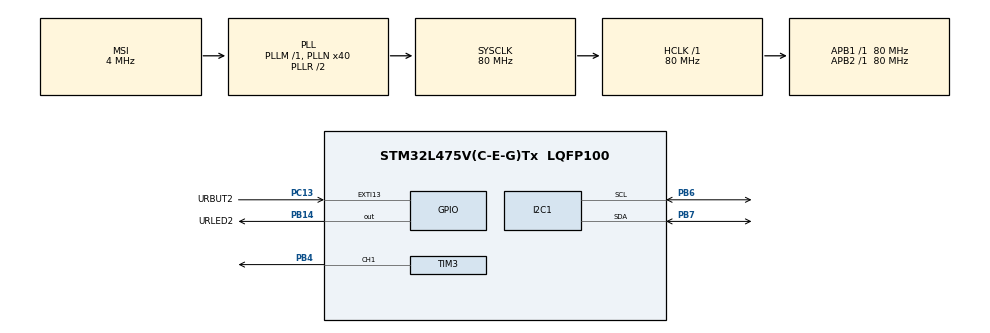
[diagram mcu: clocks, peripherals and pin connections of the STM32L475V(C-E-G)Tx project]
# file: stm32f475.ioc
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Mcu.Family=STM32L4
RCC.MSI_VALUE=4000000
PA14\ (JTCK-SWCLK).Mode=Serial_Wire
RCC.CortexFreq_Value=80000000
TIM3.AutoReloadPreload=TIM_AUTORELOAD_PRELOAD_DISABLE
PC13.Signal=GPXTI13
PB14.GPIO_Label=URLED2
PC13.GPIO_Label=URBUT2
RCC.SYSCLKSource=RCC_SYSCLKSOURCE_PLLCLK
ProjectManager.StackSize=0x400
PA14\ (JTCK-SWCLK).Signal=SYS_JTCK-SWCLK
ProjectManager.TargetToolchain=STM32CubeIDE
RCC.HCLKFreq_Value=80000000
RCC.APB2TimFreq_Value=80000000
TIM3.Period=999
PB6.Signal=I2C1_SCL
I2C1.Timing=0x10909CEC
PB6.Mode=I2C
RCC.LSE_VALUE=32768
RCC.AHBFreq_Value=80000000
TIM3.Channel-PWM\ Generation1\ CH1=TIM_CHANNEL_1
NVIC.EXTI15_10_IRQn=true\:9\:0\:true\:false\:true\:true\:true
PB14.Signal=GPIO_Output
RCC.HSE_VALUE=8000000
board=custom
RCC.VCOOutputFreq_Value=160000000
NVIC.TIM3_IRQn=true\:0\:0\:false\:false\:true\:true\:true
RCC.APB2Freq_Value=80000000
TIM3.Prescaler=1600
PB7.Signal=I2C1_SDA
SH.S_TIM3_CH1.0=TIM3_CH1,PWM Generation1 CH1
Mcu.Name=STM32L475V(C-E-G)Tx
PA13\ (JTMS-SWDIO).Mode=Serial_Wire
RCC.SYSCLKFreq_VALUE=80000000
Mcu.Package=LQFP100
PB7.Mode=I2C
ProjectManager.HeapSize=0x200
RCC.HSI_VALUE=16000000
NVIC.PriorityGroup=NVIC_PRIORITYGROUP_4
RCC.PLLN=40
RCC.APB1TimFreq_Value=80000000
PA13\ (JTMS-SWDIO).Signal=SYS_JTMS-SWDIO
RCC.APB1Freq_Value=80000000
VP_TIM3_VS_ClockSourceINT.Mode=Internal
PB4\ (NJTRST).Signal=S_TIM3_CH1

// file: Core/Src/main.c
/* USER CODE BEGIN Header */
/**
  ******************************************************************************
  * @file           : main.c
  * @brief          : Main program body
  ******************************************************************************
  * @attention
  *
  * <h2><center>&copy; Copyright (c) 2021 STMicroelectronics.
  * All rights reserved.</center></h2>
  *
  * This software component is licensed by ST under BSD 3-Clause license,
  * the "License"; You may not use this file except in compliance with the
  * License. You may obtain a copy of the License at:
  *                        opensource.org/licenses/BSD-3-Clause
  *
  ******************************************************************************
  */
/* USER CODE END Header */
#include "main.h"

I2C_HandleTypeDef hi2c1;

TIM_HandleTypeDef htim3;

void SystemClock_Config(void);
static void MX_GPIO_Init(void);
static void MX_TIM3_Init(void);
static void MX_I2C1_Init(void);

int main(void)
{

  /* MCU Configuration--------------------------------------------------------*/

  /* Reset of all peripherals, Initializes the Flash interface and the Systick. */
  HAL_Init();

  /* Configure the system clock */
  SystemClock_Config();

  /* Initialize all configured peripherals */
  MX_GPIO_Init();
  MX_TIM3_Init();
  MX_I2C1_Init();
  /* USER CODE BEGIN 2 */
  HAL_TIM_PWM_Start(&htim3, TIM_CHANNEL_1);
  uint32_t brightness=0;
  /* USER CODE END 2 */

  /* Infinite loop */
  /* USER CODE BEGIN WHILE */
  while (1)
  {
	  while( brightness < htim3.Init.Period)
	     {
	        brightness += 10;
         __HAL_TIM_SET_COMPARE(&htim3, TIM_CHANNEL_1, brightness);
	        HAL_Delay(1);

	     }
	  //PWM
//	  __HAL_TIM_SetCompare(&htim3,TIM_CHANNEL_1,100); //180
//	  HAL_Delay(1000);
//
//	  __HAL_TIM_SetCompare(&htim3,TIM_CHANNEL_1,75); //90
//	 HAL_Delay(1000);
//
//	 __HAL_TIM_SetCompare(&htim3,TIM_CHANNEL_1,50); //0
//	 HAL_Delay(1000);
	 // LED2(1000);
	 /* HAL_GPIO_TogglePin(URLED2_GPIO_Port, URLED2_Pin);
	  HAL_Delay(1000);
	  HAL_GPIO_WritePin(GPIOB, GPIO_PIN_14, GPIO_PIN_SET);
	  HAL_Delay(1000);
	  HAL_GPIO_WritePin(GPIOB, GPIO_PIN_14, GPIO_PIN_RESET);
	  HAL_Delay(1000);*/

    /* USER CODE END WHILE */

  }
}

void SystemClock_Config(void)
{
  RCC_OscInitTypeDef RCC_OscInitStruct = {0};
  RCC_ClkInitTypeDef RCC_ClkInitStruct = {0};
  RCC_PeriphCLKInitTypeDef PeriphClkInit = {0};

  /** Initializes the RCC Oscillators according to the specified parameters
  * in the RCC_OscInitTypeDef structure.
  */
  RCC_OscInitStruct.OscillatorType = RCC_OSCILLATORTYPE_MSI;
  RCC_OscInitStruct.MSIState = RCC_MSI_ON;
  RCC_OscInitStruct.MSICalibrationValue = 0;
  RCC_OscInitStruct.MSIClockRange = RCC_MSIRANGE_6;
  RCC_OscInitStruct.PLL.PLLState = RCC_PLL_ON;
  RCC_OscInitStruct.PLL.PLLSource = RCC_PLLSOURCE_MSI;
  RCC_OscInitStruct.PLL.PLLM = 1;
  RCC_OscInitStruct.PLL.PLLN = 40;
  RCC_OscInitStruct.PLL.PLLP = RCC_PLLP_DIV7;
  RCC_OscInitStruct.PLL.PLLQ = RCC_PLLQ_DIV2;
  RCC_OscInitStruct.PLL.PLLR = RCC_PLLR_DIV2;
  if (HAL_RCC_OscConfig(&RCC_OscInitStruct) != HAL_OK)
  {
    Error_Handler();
  }
  /** Initializes the CPU, AHB and APB buses clocks
  */
  RCC_ClkInitStruct.ClockType = RCC_CLOCKTYPE_HCLK|RCC_CLOCKTYPE_SYSCLK
                              |RCC_CLOCKTYPE_PCLK1|RCC_CLOCKTYPE_PCLK2;
  RCC_ClkInitStruct.SYSCLKSource = RCC_SYSCLKSOURCE_PLLCLK;
  RCC_ClkInitStruct.AHBCLKDivider = RCC_SYSCLK_DIV1;
  RCC_ClkInitStruct.APB1CLKDivider = RCC_HCLK_DIV1;
  RCC_ClkInitStruct.APB2CLKDivider = RCC_HCLK_DIV1;

  if (HAL_RCC_ClockConfig(&RCC_ClkInitStruct, FLASH_LATENCY_4) != HAL_OK)
  {
    Error_Handler();
  }
  PeriphClkInit.PeriphClockSelection = RCC_PERIPHCLK_I2C1;
  PeriphClkInit.I2c1ClockSelection = RCC_I2C1CLKSOURCE_PCLK1;
  if (HAL_RCCEx_PeriphCLKConfig(&PeriphClkInit) != HAL_OK)
  {
    Error_Handler();
  }
  /** Configure the main internal regulator output voltage
  */
  if (HAL_PWREx_ControlVoltageScaling(PWR_REGULATOR_VOLTAGE_SCALE1) != HAL_OK)
  {
    Error_Handler();
  }
}

static void MX_I2C1_Init(void)
{

  hi2c1.Instance = I2C1;
  hi2c1.Init.Timing = 0x10909CEC;
  hi2c1.Init.OwnAddress1 = 0;
  hi2c1.Init.AddressingMode = I2C_ADDRESSINGMODE_7BIT;
  hi2c1.Init.DualAddressMode = I2C_DUALADDRESS_DISABLE;
  hi2c1.Init.OwnAddress2 = 0;
  hi2c1.Init.OwnAddress2Masks = I2C_OA2_NOMASK;
  hi2c1.Init.GeneralCallMode = I2C_GENERALCALL_DISABLE;
  hi2c1.Init.NoStretchMode = I2C_NOSTRETCH_DISABLE;
  if (HAL_I2C_Init(&hi2c1) != HAL_OK)
  {
    Error_Handler();
  }
  /** Configure Analogue filter
  */
  if (HAL_I2CEx_ConfigAnalogFilter(&hi2c1, I2C_ANALOGFILTER_ENABLE) != HAL_OK)
  {
    Error_Handler();
  }
  /** Configure Digital filter
  */
  if (HAL_I2CEx_ConfigDigitalFilter(&hi2c1, 0) != HAL_OK)
  {
    Error_Handler();
  }

}

static void MX_TIM3_Init(void)
{

  TIM_ClockConfigTypeDef sClockSourceConfig = {0};
  TIM_MasterConfigTypeDef sMasterConfig = {0};
  TIM_OC_InitTypeDef sConfigOC = {0};

  htim3.Instance = TIM3;
  htim3.Init.Prescaler = 1600;
  htim3.Init.CounterMode = TIM_COUNTERMODE_UP;
  htim3.Init.Period = 999;
  htim3.Init.ClockDivision = TIM_CLOCKDIVISION_DIV1;
  htim3.Init.AutoReloadPreload = TIM_AUTORELOAD_PRELOAD_DISABLE;
  if (HAL_TIM_Base_Init(&htim3) != HAL_OK)
  {
    Error_Handler();
  }
  sClockSourceConfig.ClockSource = TIM_CLOCKSOURCE_INTERNAL;
  if (HAL_TIM_ConfigClockSource(&htim3, &sClockSourceConfig) != HAL_OK)
  {
    Error_Handler();
  }
  if (HAL_TIM_PWM_Init(&htim3) != HAL_OK)
  {
    Error_Handler();
  }
  sMasterConfig.MasterOutputTrigger = TIM_TRGO_RESET;
  sMasterConfig.MasterSlaveMode = TIM_MASTERSLAVEMODE_DISABLE;
  if (HAL_TIMEx_MasterConfigSynchronization(&htim3, &sMasterConfig) != HAL_OK)
  {
    Error_Handler();
  }
  sConfigOC.OCMode = TIM_OCMODE_PWM1;
  sConfigOC.Pulse = 0;
  sConfigOC.OCPolarity = TIM_OCPOLARITY_HIGH;
  sConfigOC.OCFastMode = TIM_OCFAST_DISABLE;
  if (HAL_TIM_PWM_ConfigChannel(&htim3, &sConfigOC, TIM_CHANNEL_1) != HAL_OK)
  {
    Error_Handler();
  }
  HAL_TIM_MspPostInit(&htim3);

}

static void MX_GPIO_Init(void)
{
  GPIO_InitTypeDef GPIO_InitStruct = {0};

  /* GPIO Ports Clock Enable */
  __HAL_RCC_GPIOC_CLK_ENABLE();
  __HAL_RCC_GPIOB_CLK_ENABLE();
  __HAL_RCC_GPIOA_CLK_ENABLE();

  /*Configure GPIO pin Output Level */
  HAL_GPIO_WritePin(URLED2_GPIO_Port, URLED2_Pin, GPIO_PIN_RESET);

  /*Configure GPIO pin : URBUT2_Pin */
  GPIO_InitStruct.Pin = URBUT2_Pin;
  GPIO_InitStruct.Mode = GPIO_MODE_IT_RISING;
  GPIO_InitStruct.Pull = GPIO_NOPULL;
  HAL_GPIO_Init(URBUT2_GPIO_Port, &GPIO_InitStruct);

  /*Configure GPIO pin : URLED2_Pin */
  GPIO_InitStruct.Pin = URLED2_Pin;
  GPIO_InitStruct.Mode = GPIO_MODE_OUTPUT_PP;
  GPIO_InitStruct.Pull = GPIO_NOPULL;
  GPIO_InitStruct.Speed = GPIO_SPEED_FREQ_LOW;
  HAL_GPIO_Init(URLED2_GPIO_Port, &GPIO_InitStruct);

  /* EXTI interrupt init*/
  HAL_NVIC_SetPriority(EXTI15_10_IRQn, 9, 0);
  HAL_NVIC_EnableIRQ(EXTI15_10_IRQn);

}

/* USER CODE BEGIN 4 */
/*short set_urled2=false;
void HAL_GPIO_EXIT_Callback(uint16_t GPIO_Pin)
{
	if (GPIO_Pin ==URBUT2_Pin)
	{
		HAL_GPIO_WritePin(URLED2_GPIO_Port,URLED2_Pin,GPIO_PIN_SET);
		set_urled2=ture;
	}
	else
	{
		HAL_GPIO_WritePin(URLED2_GPIO_Port,URLED2_Pin,GPIO_PIN_RESET);
		set_urled2=false;
	}
}*/
/* USER CODE END 4 */

void Error_Handler(void)
{
  __disable_irq();
  while (1)
  {
  }
}

/************************ (C) COPYRIGHT STMicroelectronics *****END OF FILE****/
